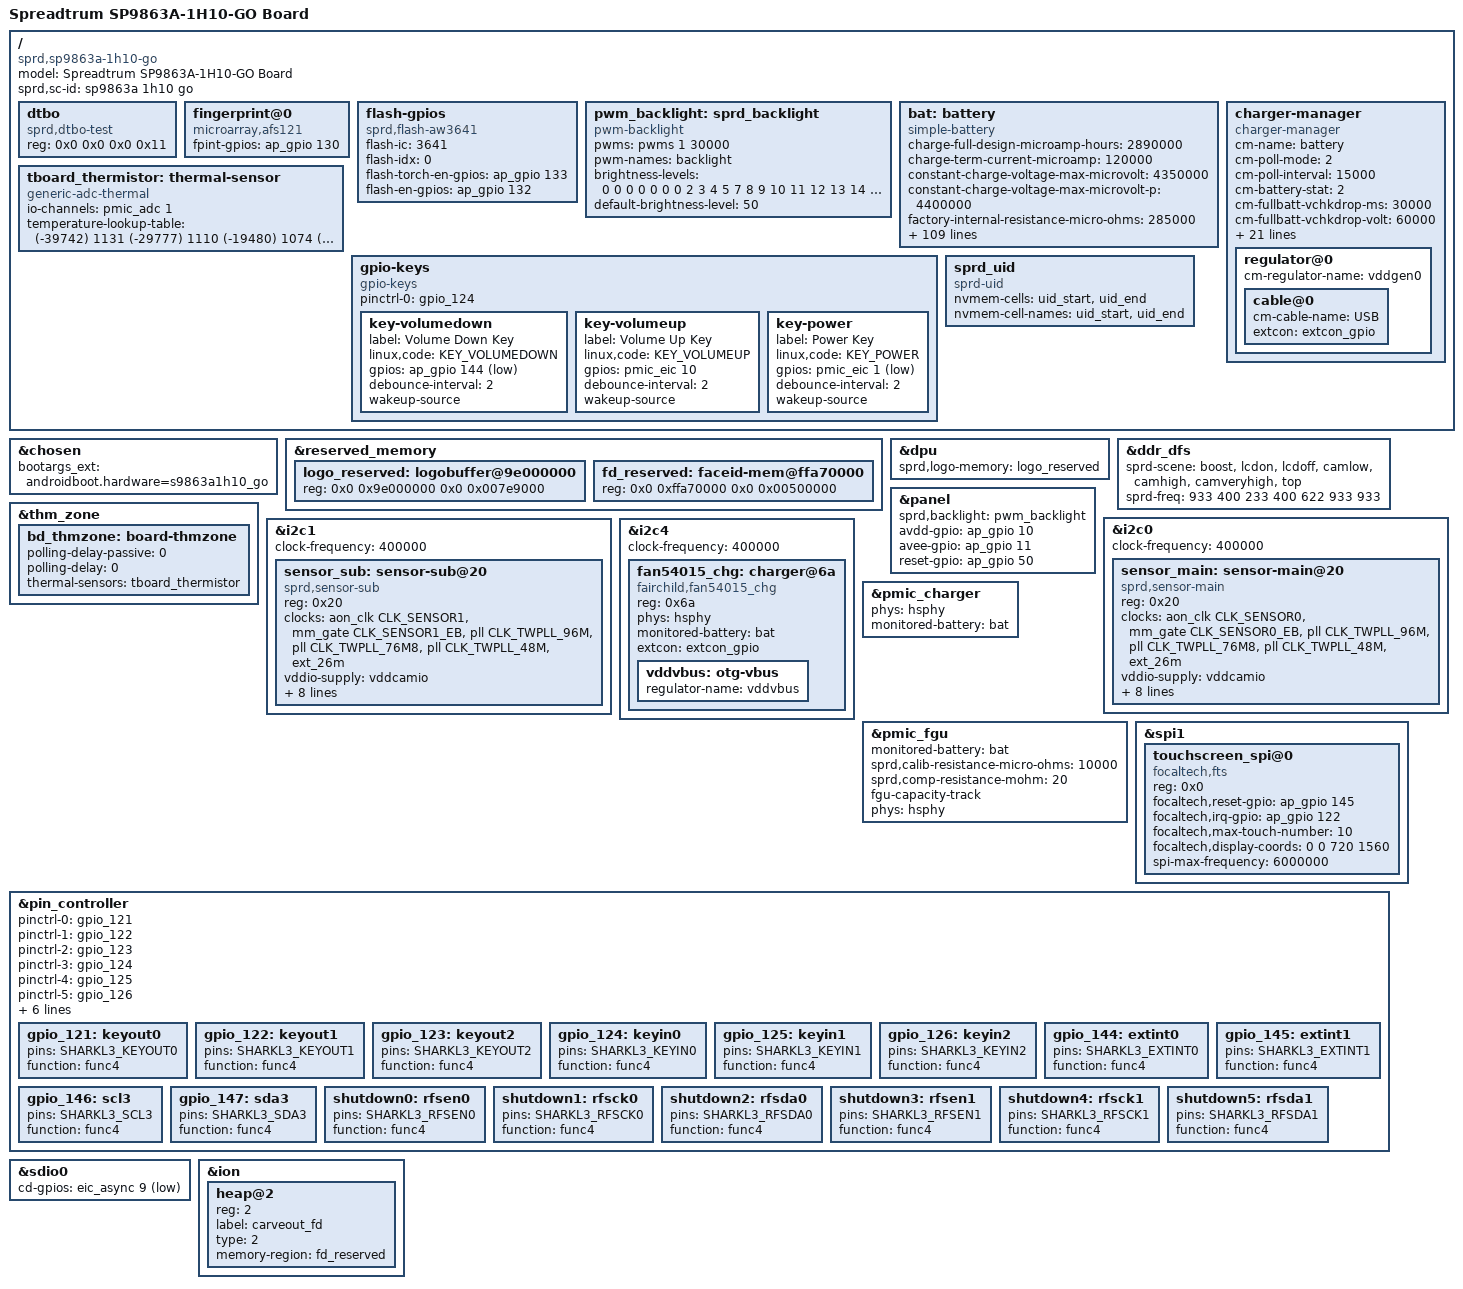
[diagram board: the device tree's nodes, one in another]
/dts-v1/;
/plugin/;
#include <dt-bindings/input/input.h>
#include <dt-bindings/gpio/gpio.h>
#include <dt-bindings/clock/sprd,sc9863a-clk.h>
#include "lcd/lcd_ft8006s_hx_hkc_mipi_nova.dtsi"
#include "lcd/lcd_st7123_dzx_hkc_mipi_nova.dtsi"
#include "lcd/lcd_dummy_mipi.dtsi"

/ {
	model = "Spreadtrum SP9863A-1H10-GO Board";

	compatible = "sprd,sp9863a-1h10-go", "sprd,sc9863a";

	sprd,sc-id = "sp9863a 1h10 go";

	fragment {
		target-path = "/";
		__overlay__ {
			#address-cells = <2>;
			#size-cells = <2>;
			dtbo: dtbo {
				compatible = "sprd,dtbo-test";
				reg = <0x0 0x0 0x0 0x11>;
			};

			fingerprint@0 {
				compatible = "microarray,afs121";
				fpint-gpios = <&ap_gpio 130 0>;
			};
			
			flash-gpios {
				compatible = "sprd,flash-aw3641";
				flash-ic = <3641>;
	
				flash-idx = <0>;
				flash-torch-en-gpios = <&ap_gpio 133 0>;
				flash-en-gpios = <&ap_gpio 132 0>;
			};
			
			pwm_backlight: sprd_backlight {
				compatible = "pwm-backlight";
				pwms = <&pwms 1 30000>;
				pwm-names = "backlight";
				brightness-levels = <
								  0   0   0   0
					  0   0   0   2   3   4   5   7   8   9
					 10  11  12  13  14  15  16  17  18  19
					 20  21  22  23  24  25  26  27  28  29
					 30  31  32  33  34  35  36  37  38  39
					 40  41  42  43  44  45  46  47  48  49
					 50  51  52  53  54  55  56  57  58  59
					 60  61  62  63  64  65  66  67  68  69
					 70  71  72  73  74  75  76  77  78  79
					 80  81  82  83  84  85  86  87  88  89
					 90  91  92  93  94  95  96  97  98  99
					100 101 102 103 104 105 106 107 108 109
					110 111 112 113 114 115 116 117 118 119
					120 121 122 123 124 125 126 127 128 129
					130 131 132 133 134 135 136 137 138 139
					140 141 142 143 144 145 146 147 148 149
					150 151 152 153 154 155 156 157 158 159
					160 161 162 163 164 165 166 167 168 169
					170 171 172 173 174 175 176 177 178 179
					180 181 182 183 184 185 186 187 188 189
					190 191 192 193 194 195 196 197 198 199
					200 201 202 203 204 205 206 207 208 209
					210 211 212 213 214 215 216 217 218 219
					220 221 222 223 224 225 226 227 228 229
					230 231 232 233 234 235 236 237 238 239
					240 241 242 243 244 245 246 247 248 249
					250 251
				>;
				default-brightness-level = <50>;
			};

			bat: battery {
				compatible = "simple-battery";
				charge-full-design-microamp-hours = <2890000>;
				charge-term-current-microamp = <120000>;
				constant-charge-voltage-max-microvolt = <4350000>;
				constant-charge-voltage-max-microvolt-p = <4400000>;
				factory-internal-resistance-micro-ohms = <285000>;
				voltage-min-design-microvolt = <3450000>;
				fullbatt-voltage = <4300000>;
				fullbatt-voltage-p = <4400000>;
				fullbatt-current = <120000>;
				fullbatt-track-end-vol = <4295000>;
				fullbatt-track-end-cur = <130000>;
				first-calib-voltage = <3625000>;
				first-calib-capacity = <40>;

				ocv-capacity-celsius = <20>;
				ocv-capacity-table-0 = <4291000 100>, <4229000 95>, <4176000 90>,
							<4125000 85>, <4078000 80>, <4033000 75>,
							<3975000 70>, <3951000 65>, <3915000 60>,
							<3863000 55>, <3835000 50>, <3814000 45>,
							<3797000 40>, <3784000 35>, <3772000 30>,
							<3757000 25>, <3740000 20>, <3715000 15>,
							<3687000 10>, <3675000 5>, <3400000 0>;
							
				 voltage-temp-table = <1095000 800>, <986000 850>, <878000 900>,
						    <775000 950>, <678000 1000>, <590000 1050>,
						    <510000 1100>, <440000 1150>, <378000 1200>,
						    <324000 1250>, <278000 1300>, <238000 1350>,
						    <204000 1400>, <175000 1450>, <150000 1500>,
						    <129000 1550>, <111000 1600>, <96000 1650>;			
				
				capacity-temp-table = <25 100>, <10 97>, <(-10) 60>;
				resistance-temp-table = <20 100>, <10 243>, <(-10) 468>;

				battery-internal-resistance-celsius = <(-20)>, <(-10)>, <0>, <10>,
					<25>, <35>, <45>, <55>;
				battery-internal-resistance-table-0 = <1224>, <1224>, <1140>,
					<1084>, <1034>, <1001>, <994>, <992>, <992>, <992>,
					<996>, <1002>, <1010>, <1024>, <1045>, <1072>, <1180>,
					<1393>, <1756>, <2461>, <4272>;
				battery-internal-resistance-table-1 = <893>, <893>, <818>, <767>,
					<743>, <705>, <685>, <684>, <678>, <675>, <672>, <673>,
					<679>, <691>, <709>, <734>, <765>, <799>, <839>, <899>,
					<1092>;
				battery-internal-resistance-table-2 = <407>, <407>, <402>, <423>,
					<429>, <428>, <409>, <416>, <408>, <395>, <390>, <390>,
					<393>, <398>, <405>, <416>, <431>, <452>, <492>, <585>,
					<730>;
				battery-internal-resistance-table-3 = <381>, <381>, <378>, <371>,
					<366>, <374>, <358>, <364>, <349>, <332>, <327>, <329>,
					<334>, <340>, <350>, <366>, <386>, <417>, <475>, <585>,
					<771>;
				battery-internal-resistance-table-4 = <182>, <182>, <179>, <179>,
					<179>, <181>, <182>, <195>, <194>, <173>, <164>, <164>,
					<167>, <171>, <175>, <174>, <172>, <179>, <187>, <244>,
					<311>;
				battery-internal-resistance-table-5 = <168>, <168>, <175>, <172>,
					<171>, <171>, <173>, <184>, <176>, <153>, <147>, <147>,
					<150>, <153>, <156>, <152>, <149>, <154>, <158>, <206>,
					<255>;
				battery-internal-resistance-table-6 = <123>, <123>, <122>, <122>,
					<123>, <126>, <130>, <138>, <143>, <120>, <115>, <116>,
					<119>, <124>, <129>, <120>, <117>, <119>, <117>, <139>,
					<156>;
				battery-internal-resistance-table-7 = <106>, <106>, <106>, <106>,
					<108>, <110>, <113>, <119>, <128>, <107>, <104>, <105>,
					<108>, <112>, <117>, <107>, <106>, <107>, <105>, <127>,
					<140>;
				battery-internal-resistance-ocv-table = <4339000>, <4276000>,
					<4221000>, <4169000>, <4118000>, <4072000>, <4022000>,
					<3983000>, <3942000>, <3892000>, <3857000>, <3833000>,
					<3813000>, <3797000>, <3783000>, <3766000>, <3746000>,
					<3723000>, <3693000>, <3680000>, <3439000>;

				charge-sdp-current-microamp = <500000 500000>;
				charge-dcp-current-microamp = <1150000 1150000>;
				charge-cdp-current-microamp = <1150000 1150000>;
				charge-unknown-current-microamp = <500000 500000>;

				charge-sdp-current-microamp-p = <500000 500000>;
				charge-dcp-current-microamp-p = <2100000 2100000>;
				charge-cdp-current-microamp-p = <2100000 2100000>;
				charge-unknown-current-microamp-p = <500000 500000>;
				
				dcp-jeita-temp-table = <1000 1030 0 4350000>,
					<1150 1180 700000 4350000>,
					<1450 1420 1150000 4350000>,
					<1550 1520 700000 4100000>;
				sdp-jeita-temp-table = <1000 1030 0 4350000>,
					<1150 1180 500000 4350000>,
					<1450 1420 500000 4350000>,
					<1550 1520 500000 4100000>;
				cdp-jeita-temp-table = <1000 1030 0 4350000>,
					<1150 1180 700000 4350000>,
					<1450 1420 1150000 4350000>,
					<1550 1520 700000 4100000>;
				unknown-jeita-temp-table = <1000 1030 0 4350000>,
					<1150 1180 500000 4350000>,
					<1450 1420 500000 4350000>,
					<1550 1520 500000 4100000>;

				dcp-jeita-temp-table-p = <1000 1030 0 4400000>,
					<1150 1180 700000 4400000>,
					<1450 1420 2100000 4400000>,
					<1550 1520 700000 4100000>;
				sdp-jeita-temp-table-p = <1000 1030 0 4400000>,
					<1150 1180 500000 4400000>,
					<1450 1420 500000 4400000>,
					<1550 1520 500000 4100000>;
				cdp-jeita-temp-table-p = <1000 1030 0 4400000>,
					<1150 1180 700000 4400000>,
					<1450 1420 2100000 4400000>,
					<1550 1520 700000 4100000>;
				unknown-jeita-temp-table-p = <1000 1030 0 4400000>,
					<1150 1180 500000 4400000>,
					<1450 1420 500000 4400000>,
					<1550 1520 500000 4100000>;
					
				force-jeita-status = <2>;
			};

			charger-manager {
				status = "okay";
				compatible = "charger-manager";
				cm-name = "battery";
				cm-poll-mode = <2>;
				cm-poll-interval = <15000>;
				cm-battery-stat = <2>;

				cm-fullbatt-vchkdrop-ms = <30000>;
				cm-fullbatt-vchkdrop-volt = <60000>;
				cm-fullbatt-capacity = <100>;

				cm-num-chargers = <1>;
				cm-chargers = "sc2721_charger";
				cm-chargers-4000mAh = "fan54015_charger";
				cm-fuel-gauge = "sc27xx-fgu";

				/* in deci centigrade */
				cm-battery-cold = <200>;
				cm-battery-cold-in-minus;
				cm-battery-hot = <800>;
				cm-battery-temp-diff = <100>;

				/* Allow charging for 6hr */
				cm-charging-max = <21600000>;
				/* recovery charging after stop charging 45min */
				cm-discharging-max = <2700000>;

				/* the interval to feed charger watchdog */
				cm-wdt-interval = <0>;

				/* drop voltage in microVolts to allow shutdown */
				cm-shutdown-voltage = <3100000>;

				/* when 99% of the time is exceeded, it will be forced to 100% */
				cm-tickle-time-out = <1500>;

				/* how much time to allow capacity change */
				cm-one-cap-time = <30>;

				/* when the safe charging voltage is exceeded, stop charging */
				cm-charge-voltage-max = <6500000>;
				/* drop voltage in microVolts to restart charging */
				cm-charge-voltage-drop = <700000>;

				monitored-battery = <&bat>;

				cm-thermal-zone = "board-thmzone";

				cm-cap-remap-table = <1 2 3>, <2 3 2>, <98 99 2>, <99 100 3>;

				regulator@0 {
					cm-regulator-name = "vddgen0";
					cable@0 {
						cm-cable-name = "USB";
						extcon = <&extcon_gpio>;
					};
				};
			};

			tboard_thermistor:thermal-sensor {
				compatible = "generic-adc-thermal";
				#thermal-sensor-cells = <0>;
				io-channels = <&pmic_adc 1>;
				io-channel-names = "sensor-channel";
				temperature-lookup-table = < (-39742) 1131
							(-29777) 1110
							(-19480) 1074
							(-4679) 983
							10110 838
							24805 654
							44922 413
							54903 316
							64895 238
							74884 178
							84883 133
							94883 100
							104880 75
							114889 57
							124872 43 >;
			};

			gpio-keys {
				compatible = "gpio-keys";
				pinctrl-names = "gpio_124";
				pinctrl-0 = <&gpio_124>;
				key-volumedown {
					label = "Volume Down Key";
					linux,code = <KEY_VOLUMEDOWN>;
					gpios = <&ap_gpio 144 GPIO_ACTIVE_LOW>;
					debounce-interval = <2>;
					wakeup-source;
				};
				key-volumeup {
					label = "Volume Up Key";
					linux,code = <KEY_VOLUMEUP>;
					gpios = <&pmic_eic 10 GPIO_ACTIVE_HIGH>;
					debounce-interval = <2>;
					wakeup-source;
				};
				key-power {
					label = "Power Key";
					linux,code =<KEY_POWER>;
					gpios = <&pmic_eic 1 GPIO_ACTIVE_LOW>;
					debounce-interval = <2>;
					wakeup-source;
				};
			};
			sprd_uid {
				compatible = "sprd-uid";
				nvmem-cells = <&uid_start>, <&uid_end>;
				nvmem-cell-names = "uid_start", "uid_end";
			};
		};
	};
};

&chosen {
	bootargs_ext = "androidboot.hardware=s9863a1h10_go";
};

&reserved_memory {
	#address-cells = <2>;
	#size-cells = <2>;

	logo_reserved: logobuffer@9e000000 {
		reg = <0x0 0x9e000000 0x0 0x007e9000>;
	};

	fd_reserved: faceid-mem@ffa70000{
		reg = <0x0 0xffa70000 0x0 0x00500000>;
	};
};

&dpu {
	sprd,logo-memory = <&logo_reserved>;
};


&ddr_dfs {
	sprd-scene = "boost", "lcdon", "lcdoff", "camlow",
		"camhigh", "camveryhigh", "top";
	sprd-freq = <933 400 233 400 622 933 933>;
};

&panel {
	sprd,backlight = <&pwm_backlight>;
	avdd-gpio = <&ap_gpio 10 GPIO_ACTIVE_HIGH>;
	avee-gpio = <&ap_gpio 11 GPIO_ACTIVE_HIGH>;
	reset-gpio = <&ap_gpio 50 GPIO_ACTIVE_HIGH>;
};

&thm_zone {
	bd_thmzone: board-thmzone {
		polling-delay-passive = <0>;
		polling-delay = <0>;
		thermal-sensors = <&tboard_thermistor>;
	};
};

&i2c0 {
	#address-cells = <1>;
	#size-cells = <0>;

	status = "okay";
	clock-frequency = <400000>;

	sensor_main: sensor-main@20 {
		compatible = "sprd,sensor-main";
		reg = <0x20>;
		clock-names = "clk_src","sensor_eb",
			"clk_96m","clk_76m8",
			"clk_48m","clk_26m";
		clocks = <&aon_clk CLK_SENSOR0>, <&mm_gate CLK_SENSOR0_EB>,
			<&pll CLK_TWPLL_96M>,<&pll CLK_TWPLL_76M8>,
			<&pll CLK_TWPLL_48M>,<&ext_26m>;
		vddio-supply = <&vddcamio>;
		vddcama-supply = <&vddcama>;
		vddcamd-supply = <&vddcamd>;
		vddcammot-supply = <&vddcammot>;
		sprd,phyid = <1>;
		csi = <&csi0>;
		//avdd-gpios=<&ap_gpio 73 0>;
		reset-gpios = <&ap_gpio 44 0>;
		power-down-gpios = <&ap_gpio 46 0>;
		power-domains = <&mm_domain>;
	};
};

&i2c1 {
	#address-cells = <1>;
	#size-cells = <0>;

	status = "okay";
	clock-frequency = <400000>;
	
	sensor_sub: sensor-sub@20 {
		compatible = "sprd,sensor-sub";
		reg = <0x20>;
		clock-names = "clk_src","sensor_eb",
			"clk_96m","clk_76m8",
			"clk_48m","clk_26m";
		clocks = <&aon_clk CLK_SENSOR1>, <&mm_gate CLK_SENSOR1_EB>,
			<&pll CLK_TWPLL_96M>,<&pll CLK_TWPLL_76M8>,
			<&pll CLK_TWPLL_48M>,<&ext_26m>;
		vddio-supply = <&vddcamio>;
		vddcama-supply = <&vddcama>;
		vddcamd-supply = <&vddcamd>;
		vddcammot-supply = <&vddcammot>;
		sprd,phyid = <4>;
		csi = <&csi0>;
		//avdd-gpios=<&ap_gpio 73 0>;
		reset-gpios = <&ap_gpio 41 0>;
		power-down-gpios = <&ap_gpio 40 0>;
		power-domains = <&mm_domain>;
	};
};
//QinJinke
&i2c4 {
	#address-cells = <1>;
	#size-cells = <0>;

	status = "okay";
	clock-frequency = <400000>;
	
	fan54015_chg: charger@6a {
		compatible = "fairchild,fan54015_chg";
		reg = <0x6a>;
		phys = <&hsphy>;
		monitored-battery = <&bat>;
		extcon = <&extcon_gpio>;
		vddvbus:otg-vbus {
			regulator-name = "vddvbus";
		};
	};
};
//QinJinke
&pmic_charger {
	status = "okay";
	phys = <&hsphy>;
	monitored-battery = <&bat>;
};

&pmic_fgu {
	monitored-battery = <&bat>;
	sprd,calib-resistance-micro-ohms = <10000>;
	sprd,comp-resistance-mohm = <20>;

	fgu-capacity-track;
	phys = <&hsphy>;
};

&spi1 {
	status = "okay";
	#address-cells = <1>;
	#size-cells = <0>;

	touchscreen_spi@0 {
		status = "okay";
		compatible = "focaltech,fts";
		reg = <0x0>;
		focaltech,reset-gpio = <&ap_gpio 145 GPIO_ACTIVE_HIGH>;
		focaltech,irq-gpio = <&ap_gpio 122 GPIO_ACTIVE_HIGH>;
		focaltech,max-touch-number = <10>;
		focaltech,display-coords =  <0 0 720 1560>;
		spi-max-frequency = <6000000>;
	};
};	


&pin_controller {
	pinctrl-names =
	/* keyout0 ~ keyout2 */
	"gpio_121", "gpio_122", "gpio_123",
	/* keyin0 ~ keyin2 */
	"gpio_124", "gpio_125", "gpio_126",
	/* extint0, extint1, scl3, sda3 */
	"gpio_144", "gpio_145", "gpio_146", "gpio_147",
	/* Note:If create a new board,need to add the shutdown node */
	"shutdown";
	pinctrl-0 = <&gpio_121>;
	pinctrl-1 = <&gpio_122>;
	pinctrl-2 = <&gpio_123>;
	pinctrl-3 = <&gpio_124>;
	pinctrl-4 = <&gpio_125>;
	pinctrl-5 = <&gpio_126>;
	pinctrl-6 = <&gpio_144>;
	pinctrl-7 = <&gpio_145>;
	pinctrl-8 = <&gpio_146>;
	pinctrl-9 = <&gpio_147>;
	pinctrl-10 = <&shutdown0
			&shutdown1
			&shutdown2
			&shutdown3
			&shutdown4
			&shutdown5>;

	gpio_121: keyout0 {
		pins = "SHARKL3_KEYOUT0";
		function = "func4";
	};

	gpio_122: keyout1 {
		pins = "SHARKL3_KEYOUT1";
		function = "func4";
	};

	gpio_123: keyout2 {
		pins = "SHARKL3_KEYOUT2";
		function = "func4";
	};

	gpio_124: keyin0 {
		pins = "SHARKL3_KEYIN0";
		function = "func4";
	};

	gpio_125: keyin1 {
		pins = "SHARKL3_KEYIN1";
		function = "func4";
	};

	gpio_126: keyin2 {
		pins = "SHARKL3_KEYIN2";
		function = "func4";
	};

	gpio_144: extint0 {
		pins = "SHARKL3_EXTINT0";
		function = "func4";
	};

	gpio_145: extint1 {
		pins = "SHARKL3_EXTINT1";
		function = "func4";
	};

	gpio_146: scl3 {
		pins = "SHARKL3_SCL3";
		function = "func4";
	};

	gpio_147: sda3 {
		pins = "SHARKL3_SDA3";
		function = "func4";
	};

	shutdown0: rfsen0 {
		pins = "SHARKL3_RFSEN0";
		function = "func4";
	};

	shutdown1: rfsck0 {
		pins = "SHARKL3_RFSCK0";
		function = "func4";
	};

	shutdown2: rfsda0 {
		pins = "SHARKL3_RFSDA0";
		function = "func4";
	};

	shutdown3: rfsen1 {
		pins = "SHARKL3_RFSEN1";
		function = "func4";
	};

	shutdown4: rfsck1 {
		pins = "SHARKL3_RFSCK1";
		function = "func4";
	};

	shutdown5: rfsda1 {
		pins = "SHARKL3_RFSDA1";
		function = "func4";
	};
};

&sdio0 {
	cd-gpios = <&eic_async 9 1>;
};

&ion {
	#address-cells = <1>;
	#size-cells = <0>;

	heap@2 {
		reg = <2>;
		label = "carveout_fd";
		type = <2>;
		memory-region = <&fd_reserved>;
	};
};
